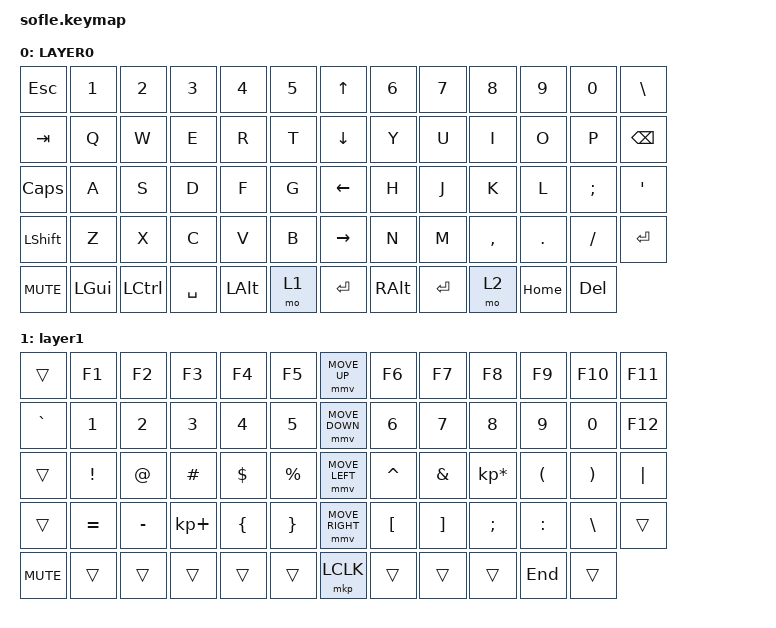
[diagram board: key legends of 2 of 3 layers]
#include <behaviors/mouse_keys.dtsi>
#include <behaviors.dtsi>
#include <dt-bindings/zmk/bt.h>
#include <dt-bindings/zmk/keys.h>
#include <dt-bindings/zmk/mouse.h>
#include <dt-bindings/zmk/outputs.h>
#include <dt-bindings/zmk/rgb.h>

#define ZMK_MOUSE_DEFAULT_MOVE_VAL 1200  // 600
#define ZMK_MOUSE_DEFAULT_SCRL_VAL 20    // 10
#define U_MS_U &mmv MOVE_UP
#define U_MS_D &mmv MOVE_DOWN
#define U_MS_L &mmv MOVE_LEFT
#define U_MS_R &mmv MOVE_RIGHT
#define ZMK_MOUSE_DEFAULT_MOVE_VAL 1200  //  600
#define ZMK_MOUSE_DEFAULT_SCRL_VAL 20    // 10

/ {
    behaviors {
        mmv {
            acceleration-exponent = <1>;      // 1
            time-to-max-speed-ms = <900>;    // 40
            delay-ms = <0>;                   // 0
        };

        msc {
            acceleration-exponent = <1>;      // 0
            time-to-max-speed-ms = <400>;      // 500
            delay-ms = <0>;                   //   10
        };
    };

    scroll_encoder: scroll_encoder {
        compatible = "zmk,behavior-sensor-rotate";
        #sensor-binding-cells = <0>;
        bindings = <&msc SCRL_DOWN>, <&msc SCRL_UP>;

        tap-ms = <30>;
    };  

    keymap {
        compatible = "zmk,keymap";

        layer0 {
            bindings = <

&kp ESC      &kp N1         &kp N2       &kp N3       &kp N4       &kp N5       &kp UP_ARROW     &kp N6     &kp N7     &kp N8     &kp N9           &kp N0      &kp BSLH
&kp TAB      &kp Q          &kp W        &kp E        &kp R        &kp T        &kp DOWN_ARROW   &kp Y      &kp U      &kp I      &kp O            &kp P       &kp BACKSPACE
&kp CAPS     &kp A          &kp S        &kp D        &kp F        &kp G        &kp LEFT_ARROW   &kp H      &kp J      &kp K      &kp L            &kp SEMI    &kp APOS
&kp LSHFT    &kp Z          &kp X        &kp C         &kp V        &kp B        &kp RIGHT_ARROW  &kp N      &kp M      &kp COMMA  &kp DOT          &kp FSLH    &kp ENTER
&kp C_MUTE   &kp LEFT_GUI   &kp LCTRL    &kp SPACE &kp LEFT_ALT   &mo 1        &kp ENTER  &kp RIGHT_ALT   &kp ENTER  &mo 2      &kp HOME  &kp DELETE
            >;

            sensor-bindings = <&inc_dec_kp C_VOLUME_UP C_VOL_DN>;
            display-name = "LAYER0";
        };

        layer_1 {
            bindings = <
&trans    &kp F1    &kp F2    &kp F3      &kp F4    &kp F5    &mmv MOVE_UP                &kp F6    &kp F7   &kp F8          &kp F9    &kp F10   &kp F11
&kp GRAVE &kp N1    &kp N2    &kp N3      &kp N4    &kp N5    &mmv MOVE_DOWN                &kp N6    &kp N7   &kp N8          &kp N9    &kp N0    &kp F12
&trans    &kp EXCL  &kp AT    &kp HASH    &kp DLLR  &kp PRCNT &mmv MOVE_LEFT                &kp CARET &kp AMPS &kp KP_MULTIPLY &kp LPAR  &kp RPAR  &kp PIPE
&trans    &kp EQUAL &kp MINUS &kp KP_PLUS &kp LBRC  &kp RBRC  &mmv MOVE_RIGHT    &kp LBKT  &kp RBKT &kp SEMI        &kp COLON &kp BSLH  &trans
&kp C_MUTE  &trans   &trans    &trans      &trans   &trans    &mkp LCLK        &trans       &trans     &trans      &kp END     &trans
            >;

            display-name = "layer1";
            sensor-bindings = <&scroll_encoder>;
        };

        layer_2 {
            bindings = <
&bt BT_CLR &bt BT_SEL 0 &bt BT_SEL 1 &bt BT_SEL 2 &bt BT_SEL 3 &bt BT_SEL 4     &mmv MOVE_UP      &trans    &trans    &trans   &trans    &trans  &trans
&trans     &kp INS      &kp PSCRN    &kp K_CMENU  &trans       &trans           &mmv MOVE_DOWN    &kp PG_UP &trans    &kp UP   &trans    &kp N0  &trans
&trans     &kp LALT     &kp LCTRL    &kp LSHFT    &trans       &kp CLCK         &mmv MOVE_LEFT    &kp PG_DN &kp LEFT  &kp DOWN &kp RIGHT &kp DEL &kp BSPC
&trans     &kp K_UNDO   &kp K_CUT    &kp K_COPY   &kp K_PASTE  &trans           &mmv MOVE_RIGHT   &trans  &trans    &trans    &trans   &trans    &trans  &trans
                        &trans       &trans       &trans       &trans  &trans   &trans  &trans    &trans    &trans   &trans
            >;

            sensor-bindings = <&scroll_encoder>;
        };
    };
};
